# LPC8N04 register map
Vendor: nxp.com; File version: 1.0
CPU: CM0PLUS r0p0, little endian, no MPU, no FPU, VTOR, 2 interrupt priority bits
Registers are 32-bit, read-write, reset 0x0 unless marked. A register's access mark holds for its fields unless they carry their own. Offsets are from the block's base; [hi:lo] are bit positions; {n}, {i} and the like mark numbered series; 'fields as' and 'values as' point back to an identical list.

## PMU — Power Management Unit
Base 0x40038000
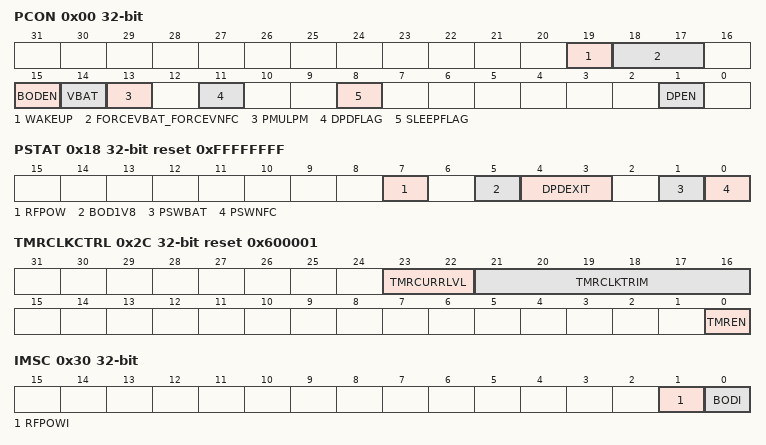
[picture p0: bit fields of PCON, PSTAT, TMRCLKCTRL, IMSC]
0x00 PCON — Power control register
  [19] WAKEUP — enable the WAKEUP function on pin PIO0_0
    0=DISABLED (WAKEUP function not enabled); 1=ENABLED (WAKEUP function assigned to PIO0_0. When selecting this option, PIO0_0 has a weak pull-up to VDD_ALON when in Deep power-down.)
  [18:17] FORCEVBAT_FORCEVNFC — force the power source selection
    1=VBAT_POWER (force to VBAT/external power); 2=NFC_POWER (force to NFC power); 3=AUTO (autoswitching if PMULPM is 0)
  [15] BODEN — Brown-out detector enable
    0=DISABLED (BOD disabled); 1=ENABLED (BOD enabled)
  [14] VBAT — This bit enables the connection of the VBAT pin to VDD, effectively connecting the system to the battery.
    0=NOT_CONNECTED (VBAT not connected to VDD); 1=CONNECTED (VBAT connected to VDD)
  [13] PMULPM — PMU ultra-low-power mod
    0=AUTO (power switches are in automatic mode); 1=FORCED (disable automatic switching (default to external power).)
  [11] DPDFLAG — Deep power-down flag
    0=CLEARED (read: No power-down mode entered / write: no effect); 1=SET (read:deep power-down mode entered / write: clear the deep power-down flag)
  [8] SLEEPFLAG — Sleep mode flag
    0=CLEARED (read: No power-down mode entered / write: no effect); 1=SET (read: sleep/deep-sleep mode entered / write: write 1 to clear SLEEPFLAG)
  [1] DPEN — Deep power-down mode enable
    0=DISABLED (ARM WFI will enter Sleep or Deep-sleep mode (clock to ARM Cortex M0+ core turned off)); 1=ENABLED (ARM WFI will enter Deep-power down mode (ARM Cortex M0+ core powered down))
{0x4+4i} GPREG{i} (i=0..4) — General purpose register {i}
  [31:0] GPDATA — Data retained during deep power-down mode
0x18 PSTAT reset 0xFFFFFFFF — Power management unit status register
  [7] RFPOW ro — RF field detected
    0=NOT_DETECTED (No field); 1=DETECTED (RF field)
  [5] BOD1V8 ro — BOD detected (VDD less 1.8 V)
    0=VDD larger 1.8 V; 1=VDD less 1.8 V
  [4:3] DPDEXIT ro — reason for exit from Deep-Power Down. Only valid when the DPDFLAG in the PCON register is asserted (1)
    0=POR or RESETN pin asserted; 1=LDO enabled; 2=RTC timer event; 3=WAKEUP pin negative edge detected
  [1] PSWBAT ro — status of battery power selection switch
    0=OPEN (Switch disabled (not conducting)); 1=CLOSED (Switch enabled (conducting))
  [0] PSWNFC ro — Status of NFC power selection switch
    values as PSWBAT
0x20 ACCSTAT — Access status register
  [0] PMU_READY ro — (0) PMU access not possible, (1) PMU access possible
0x24 LDO1V6 reset 0x4 — Analog 1.6 V LDO trimming
  [3:0] TRIM1V6 — Trim value for analog LDO
0x2C TMRCLKCTRL reset 0x600001 — Timer clock control register
  [23:22] TMRCURRLVL — Timer FRO current level selector bits
  [21:16] TMRCLKTRIM — Timer FRO trim value (6-bit)
  [0] TMREN — RTC clock source.
    0=NO_CLOCK; 1=TFRO (32kHz FRO)
0x30 IMSC — interrupt mask set and clear Register
  [1] RFPOWI — software should set this bit to enable an interrupt when RF power is detected.
  [0] BODI — software should set this bit to enable an interrupt when the BOD is triggered.
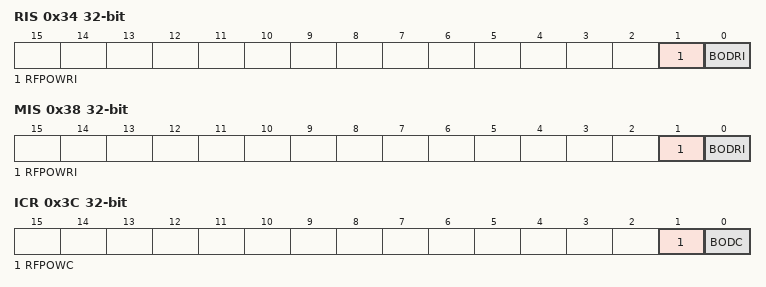
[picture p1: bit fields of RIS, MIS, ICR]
0x34 RIS — raw interrupt status register
  [1] RFPOWRI ro — raw RF power interrupt value
  [0] BODRI ro — raw BOD interrupt value.
0x38 MIS — masked interrupt status register
  fields as RIS
0x3C ICR wo reset not defined — interrupt clear register
  [1] RFPOWC — writing a logic 1 clears the RF power interrupt.
  [0] BODC — writing a logic 1 clears the BOD interrupt.

## IOCON — IO configuration
Base 0x40044000
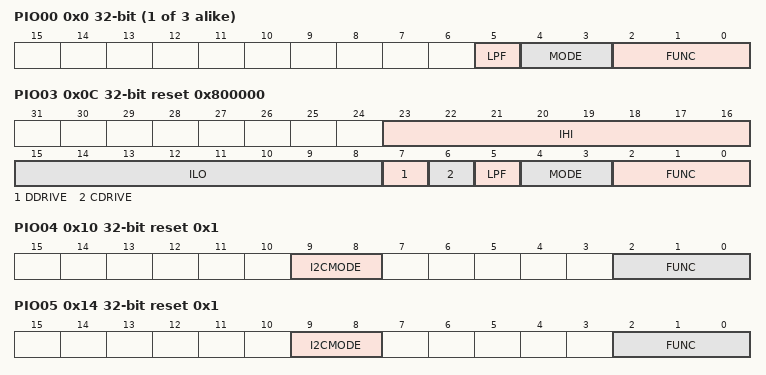
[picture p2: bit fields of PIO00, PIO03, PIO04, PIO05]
{0x0+4i} PIO{i:02} (i=0..2) — Digital I/O control for port 0 pins PIO_{i}
  [5] LPF — Low-pass filter
    0=DISABLED; 1=ENABLED
  [4:3] MODE — Selects function mode (on-chip pull-up/pull-down resistor control).
    0=INACTIVE (Inactive. Inactive (no pull-down/pull-up resistor enabled).); 1=PULL_DOWN (Pull-down. Pull-down resistor enabled.); 2=PULL_UP (Pull-up. Pull-up resistor enabled.); 3=REPEATER (Repeater. Repeater mode.)
  [2:0] FUNC — Selects pin function.
    {v}=ALT{v} (Alternative connection {v}.) (v=0..7)
0x0C PIO03 reset 0x800000 — Digital I/O control for port 0 pins PIO_3
  [23:16] IHI — Output high (asserted) value
  [15:8] ILO — Output low (deasserted) value
  [7] DDRIVE — Digital drive strength
    0=HIGH (High Drive (pad EHD0=0,EHD1=1)); 1=ULTRAHIGH (Ultra high Drive (pad EHD0=1,EHD1=1))
  [6] CDRIVE — Select pin output driver
    0=FIXED (Fixed voltage driver); 1=PROGRAMMABLE (Programmable current driver)
  [5] LPF — Low-pass filter
    0=DISABLED; 1=ENABLED
  [4:3] MODE — Selects function mode (on-chip pull-up/pull-down resistor control).
    values as PIO00.MODE
  [2:0] FUNC — Selects pin function.
    {v}=ALT{v} (Alternative connection {v}.) (v=0..7)
0x10 PIO04 reset 0x1 — Digital I/O control for port 0 pins PIO_4
  [9:8] I2CMODE — Selects I2C mode. Select Standard mode I2CMODE = 00, default) or Standard I/O functionality (I2CMODE = 01) if the pin function is GPIO (FUNC = 000).
    0=STD_FAST_I2C (Standard mode/fast-mode I2C); 1=STD_I_O (Standard I/O functionality)
  [2:0] FUNC — Selects pin function.
    {v}=ALT{v} (Alternative connection {v}.) (v=0..7)
0x14 PIO05 reset 0x1 — Digital I/O control for port 0 pins PIO_5
  fields as PIO04
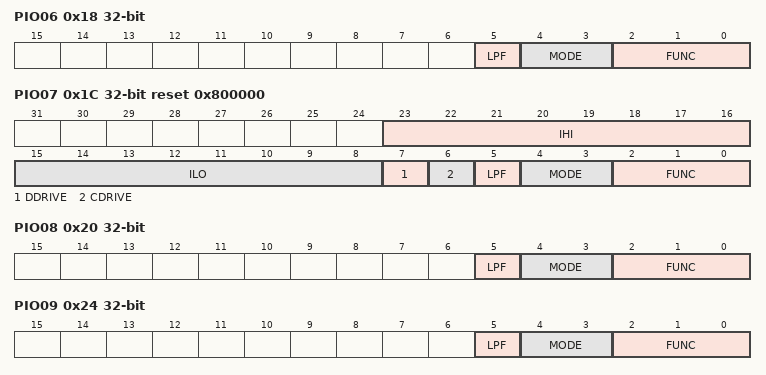
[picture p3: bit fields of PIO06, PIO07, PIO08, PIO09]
0x18 PIO06 — Digital I/O control for port 0 pins PIO_6
  fields as PIO00
0x1C PIO07 reset 0x800000 — Digital I/O control for port 0 pins PIO_7
  fields as PIO03
0x20 PIO08 — Digital I/O control for port 0 pins PIO_8
  fields as PIO00
0x24 PIO09 — Digital I/O control for port 0 pins PIO_9
  fields as PIO00
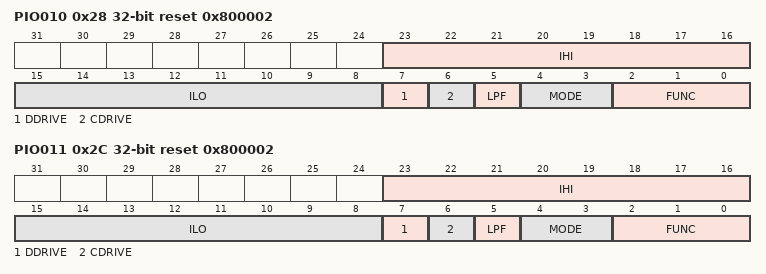
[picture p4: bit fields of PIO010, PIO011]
0x28 PIO010 reset 0x800002 — Digital I/O control for port 0 pins PIO_10
  fields as PIO03
0x2C PIO011 reset 0x800002 — Digital I/O control for port 0 pins PIO_11
  fields as PIO03
